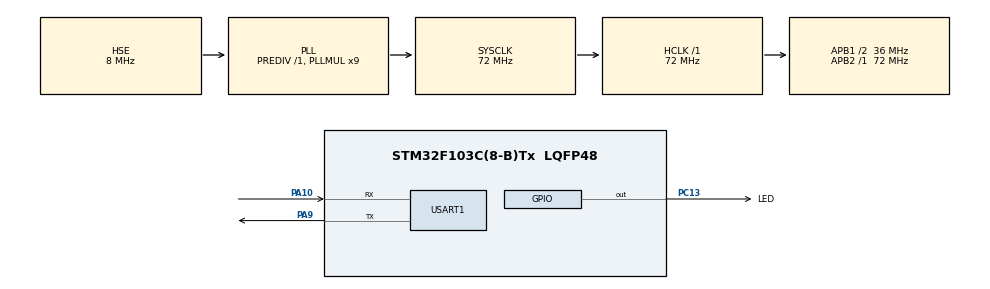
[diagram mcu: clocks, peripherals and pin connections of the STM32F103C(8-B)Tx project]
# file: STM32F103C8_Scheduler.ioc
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Mcu.Family=STM32F1
Mcu.Name=STM32F103C(8-B)Tx
Mcu.Package=LQFP48
NVIC.PriorityGroup=NVIC_PRIORITYGROUP_4
NVIC.TIM3_IRQn=true\:0\:0\:false\:false\:true\:true\:true\:true
NVIC.USART1_IRQn=true\:0\:0\:false\:false\:true\:true\:true\:true
PA10.Mode=Asynchronous
PA10.Signal=USART1_RX
PA13.Mode=Serial_Wire
PA13.Signal=SYS_JTMS-SWDIO
PA14.Mode=Serial_Wire
PA14.Signal=SYS_JTCK-SWCLK
PA9.Mode=Asynchronous
PA9.Signal=USART1_TX
PC13-TAMPER-RTC.GPIO_Label=LED
PC13-TAMPER-RTC.Signal=GPIO_Output
PD0-OSC_IN.Mode=HSE-External-Oscillator
PD0-OSC_IN.Signal=RCC_OSC_IN
PD1-OSC_OUT.Mode=HSE-External-Oscillator
PD1-OSC_OUT.Signal=RCC_OSC_OUT
ProjectManager.HeapSize=0x200
ProjectManager.StackSize=0x400
ProjectManager.TargetToolchain=Makefile
RCC.AHBFreq_Value=72000000
RCC.APB1CLKDivider=RCC_HCLK_DIV2
RCC.APB1Freq_Value=36000000
RCC.APB1TimFreq_Value=72000000
RCC.APB2Freq_Value=72000000
RCC.APB2TimFreq_Value=72000000
RCC.HCLKFreq_Value=72000000
RCC.PLLMUL=RCC_PLL_MUL9
RCC.PLLSourceVirtual=RCC_PLLSOURCE_HSE
RCC.SYSCLKFreq_VALUE=72000000
RCC.SYSCLKSource=RCC_SYSCLKSOURCE_PLLCLK
RCC.USBFreq_Value=72000000
TIM3.AutoReloadPreload=TIM_AUTORELOAD_PRELOAD_ENABLE
TIM3.Period=100-1
TIM3.Prescaler=720-1
USART1.VirtualMode=VM_ASYNC
VP_TIM3_VS_ClockSourceINT.Mode=Internal
board=custom

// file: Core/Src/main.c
/* USER CODE BEGIN Header */
/**
  ******************************************************************************
  * @file           : main.c
  * @brief          : Main program body
  ******************************************************************************
  * @attention
  *
  * Copyright (c) 2025 STMicroelectronics.
  * All rights reserved.
  *
  * This software is licensed under terms that can be found in the LICENSE file
  * in the root directory of this software component.
  * If no LICENSE file comes with this software, it is provided AS-IS.
  *
  ******************************************************************************
  */
/* USER CODE END Header */
#include "main.h"
#include "tim.h"
#include "usart.h"
#include "gpio.h"

/* USER CODE BEGIN Includes */
#include <stdio.h>
#include "scheduler.h"
#include "led_lib.h"
/* USER CODE END Includes */

/* USER CODE BEGIN PV */
uint8_t tim3_flag = 0;

// 两张链表：任务注册表 和 就绪任务表
static TaskNode *registered_task_list = NULL;
static TaskNode *ready_task_list = NULL;
/* USER CODE END PV */

void SystemClock_Config(void);
/* USER CODE BEGIN PFP */
void task_led_toggle(void);
void task_print(void);
/* USER CODE END PFP */

int main(void)
{

  /* MCU Configuration--------------------------------------------------------*/

  /* Reset of all peripherals, Initializes the Flash interface and the Systick. */
  HAL_Init();

  /* Configure the system clock */
  SystemClock_Config();

  /* Initialize all configured peripherals */
  MX_GPIO_Init();
  MX_USART1_UART_Init();
  MX_TIM3_Init();
  /* USER CODE BEGIN 2 */
	HAL_TIM_Base_Start_IT(&htim3);

	task_pool_init();
  register_task(task_led_toggle, 500, &registered_task_list); // 每 500ms 执行一次
  register_task(task_print, 1000, &registered_task_list);     // 每 1000ms 执行一次
  /* USER CODE END 2 */

  /* Infinite loop */
  /* USER CODE BEGIN WHILE */
  while (1)
  {
		if (tim3_flag == 1) {
			tim3_flag = 0;

			scheduler_tick(registered_task_list, &ready_task_list);
			scheduler_run(&ready_task_list);
		}

    /* USER CODE END WHILE */

  }
}

void SystemClock_Config(void)
{
  RCC_OscInitTypeDef RCC_OscInitStruct = {0};
  RCC_ClkInitTypeDef RCC_ClkInitStruct = {0};

  /** Initializes the RCC Oscillators according to the specified parameters
  * in the RCC_OscInitTypeDef structure.
  */
  RCC_OscInitStruct.OscillatorType = RCC_OSCILLATORTYPE_HSE;
  RCC_OscInitStruct.HSEState = RCC_HSE_ON;
  RCC_OscInitStruct.HSEPredivValue = RCC_HSE_PREDIV_DIV1;
  RCC_OscInitStruct.HSIState = RCC_HSI_ON;
  RCC_OscInitStruct.PLL.PLLState = RCC_PLL_ON;
  RCC_OscInitStruct.PLL.PLLSource = RCC_PLLSOURCE_HSE;
  RCC_OscInitStruct.PLL.PLLMUL = RCC_PLL_MUL9;
  if (HAL_RCC_OscConfig(&RCC_OscInitStruct) != HAL_OK)
  {
    Error_Handler();
  }

  /** Initializes the CPU, AHB and APB buses clocks
  */
  RCC_ClkInitStruct.ClockType = RCC_CLOCKTYPE_HCLK|RCC_CLOCKTYPE_SYSCLK
                              |RCC_CLOCKTYPE_PCLK1|RCC_CLOCKTYPE_PCLK2;
  RCC_ClkInitStruct.SYSCLKSource = RCC_SYSCLKSOURCE_PLLCLK;
  RCC_ClkInitStruct.AHBCLKDivider = RCC_SYSCLK_DIV1;
  RCC_ClkInitStruct.APB1CLKDivider = RCC_HCLK_DIV2;
  RCC_ClkInitStruct.APB2CLKDivider = RCC_HCLK_DIV1;

  if (HAL_RCC_ClockConfig(&RCC_ClkInitStruct, FLASH_LATENCY_2) != HAL_OK)
  {
    Error_Handler();
  }
}

/* USER CODE BEGIN 4 */
void HAL_TIM_PeriodElapsedCallback(TIM_HandleTypeDef *htim)
{
	if (htim->Instance == TIM3) {
		tim3_flag = 1;
	}
}

// 示例任务函数（用户定义）
void task_led_toggle(void) {
  LED_Toggle();
}

void task_print(void) {
	static uint8_t cnt = 0;

	printf("task print runnig %d\n", cnt++);
}

/* USER CODE END 4 */

void Error_Handler(void)
{
  __disable_irq();
  while (1)
  {
  }
}
